AUTOSAR XML (schema 4-2-2)
package /AUTOSAR_DoIP/SwComponentTypes
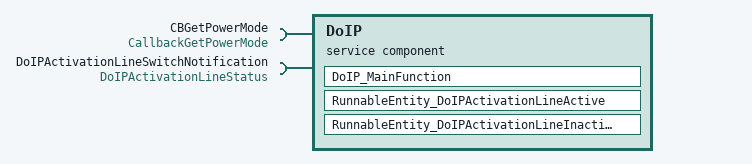
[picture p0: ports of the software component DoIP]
  service sw component type DoIP
    require port CBGetPowerMode: required-interface=CallbackGetPowerMode
    require port DoIPActivationLineSwitchNotification: mode-switch-receiver-com-spec=supports-asynchronous-mode-switch=true, required-interface=DoIPActivationLineStatus
    behavior IntBeh_DoIP: data-type-mapping=DTS_DoIP_ActivationLineType, included-data-type-set=data-type=DoIP_ActivationLineRequestType, port-api-option{enable-take-address=true, indirect-api=false, port=CBGetPowerMode}
      swc mode switch event SwcModeSwitchEvent_0: start-on-event=RunnableEntity_DoIPActivationLineActive, activation=ON-ENTRY, mode=DoIPActivationLineSwitchNotification.currentDoIPActivationLineStatus.DOIP_ACTIVATION_LINE_ACTIVE
      swc mode switch event SwcModeSwitchEvent_1: start-on-event=RunnableEntity_DoIPActivationLineInactive, activation=ON-ENTRY, mode=DoIPActivationLineSwitchNotification.currentDoIPActivationLineStatus.DOIP_ACTIVATION_LINE_INACTIVE
      runnable DoIP_MainFunction
        sync call SSC_GetPowerMode: operation=CBGetPowerMode.GetPowerMode
      runnable RunnableEntity_DoIPActivationLineActive: can-be-invoked-concurrently=true, symbol=DoIP_ActivationLineSwitchActive
      runnable RunnableEntity_DoIPActivationLineInactive: can-be-invoked-concurrently=true, symbol=DoIP_ActivationLineSwitchInactive
package /AUTOSAR_DoIP/ImplementationDataTypes
  impl type DoIP_ActivationLineRequestType: compu {1=DOIP_ACTIVATION_LINE_ACTIVE, 0=DOIP_ACTIVATION_LINE_INACTIVE}, implementation-data-type=uint8
  impl type DoIP_PowerStateType: compu {0=DOIP_NOT_READY, 1=DOIP_READY, 2=DOIP_NOT_SUPPORTED}, implementation-data-type=uint8
  data type mapping set DTS_DoIP_ActivationLineType: mode-request-type-map{implementation-data-type=DoIP_ActivationLineRequestType, mode-group=DoIP_ActivationLineType}
package /AUTOSAR_DoIP/SwcImplementations
  swc implementation Impl_DoIP: programming-language=C, sw-version=9.0.0, vendor-id=6, behavior=IntBeh_DoIP
    code-descriptors:
      code CodeDescr_DoIP: artifact-descriptors=autosar-engineering-object={short-label=Code_0, category=SWSRC}
package /AUTOSAR_DoIP/PortInterfaces
  client server interface CallbackGetPowerMode: is-service=true
    operation GetPowerMode: possible-error=[E_OK, E_NOT_OK]
      arg PowerStateReady: type=DoIP_PowerStateType, direction=OUT
    error E_OK: error-code=0
    error E_NOT_OK: error-code=1
package /AUTOSAR_DoIP/ModeDeclarationGroups
  mode declaration group DoIP_ActivationLineType: category=EXPLICIT_ORDER, initial-mode=DOIP_ACTIVATION_LINE_INACTIVE, on-transition-value=2
    mode DOIP_ACTIVATION_LINE_ACTIVE: value=1
    mode DOIP_ACTIVATION_LINE_INACTIVE: value=0
package /AUTOSAR_DoIP/ModeSwitchInterfaces
  mode switch interface DoIPActivationLineStatus
    mode group currentDoIPActivationLineStatus: type=DoIP_ActivationLineType
